VERSION "benchmark-v1"

NS_ :

BS_ :

BU_ : EngineECU Cluster

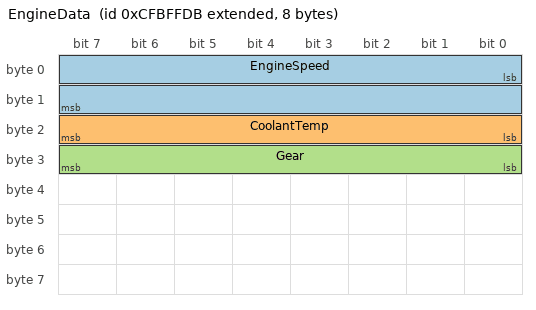
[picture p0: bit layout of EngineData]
BO_ 2365325275 EngineData: 8 EngineECU
 SG_ EngineSpeed : 0|16@1+ (0.125,0) [0|8031.875] "rpm" Cluster
 SG_ CoolantTemp : 16|8@1+ (1,-40) [-40|215] "degC" Cluster
 SG_ Gear : 24|8@1+ (1,0) [0|255] "" Cluster

BO_ 2565603072 TransportData: 8 EngineECU
 SG_ Sequence : 0|8@1+ (1,0) [0|255] "" Cluster
 SG_ PayloadFirst : 8|8@1+ (1,0) [0|255] "" Cluster

BO_ 500 VehicleStatus: 8 Cluster
 SG_ VehicleSpeed : 0|16@1+ (0.01,0) [0|655.35] "km/h" EngineECU
 SG_ Ignition : 16|1@1+ (1,0) [0|1] "" EngineECU

BO_ 801 MuxStatus: 8 EngineECU
 SG_ Selector M : 0|8@1+ (1,0) [0|255] "" Cluster
 SG_ Variant0 m0 : 8|8@1+ (1,0) [0|255] "count" Cluster

CM_ BO_ 217841627 "Representative dense and sparse timeseries message";
CM_ SG_ 217841627 EngineSpeed "Current engine speed";
VAL_ 217841627 Gear 0 "Neutral" 1 "First" 2 "Second" 3 "Third" ;
VAL_ 500 Ignition 0 "Off" 1 "On" ;
VAL_ 801 Selector 0 "Base" 1 "Alternate" ;
